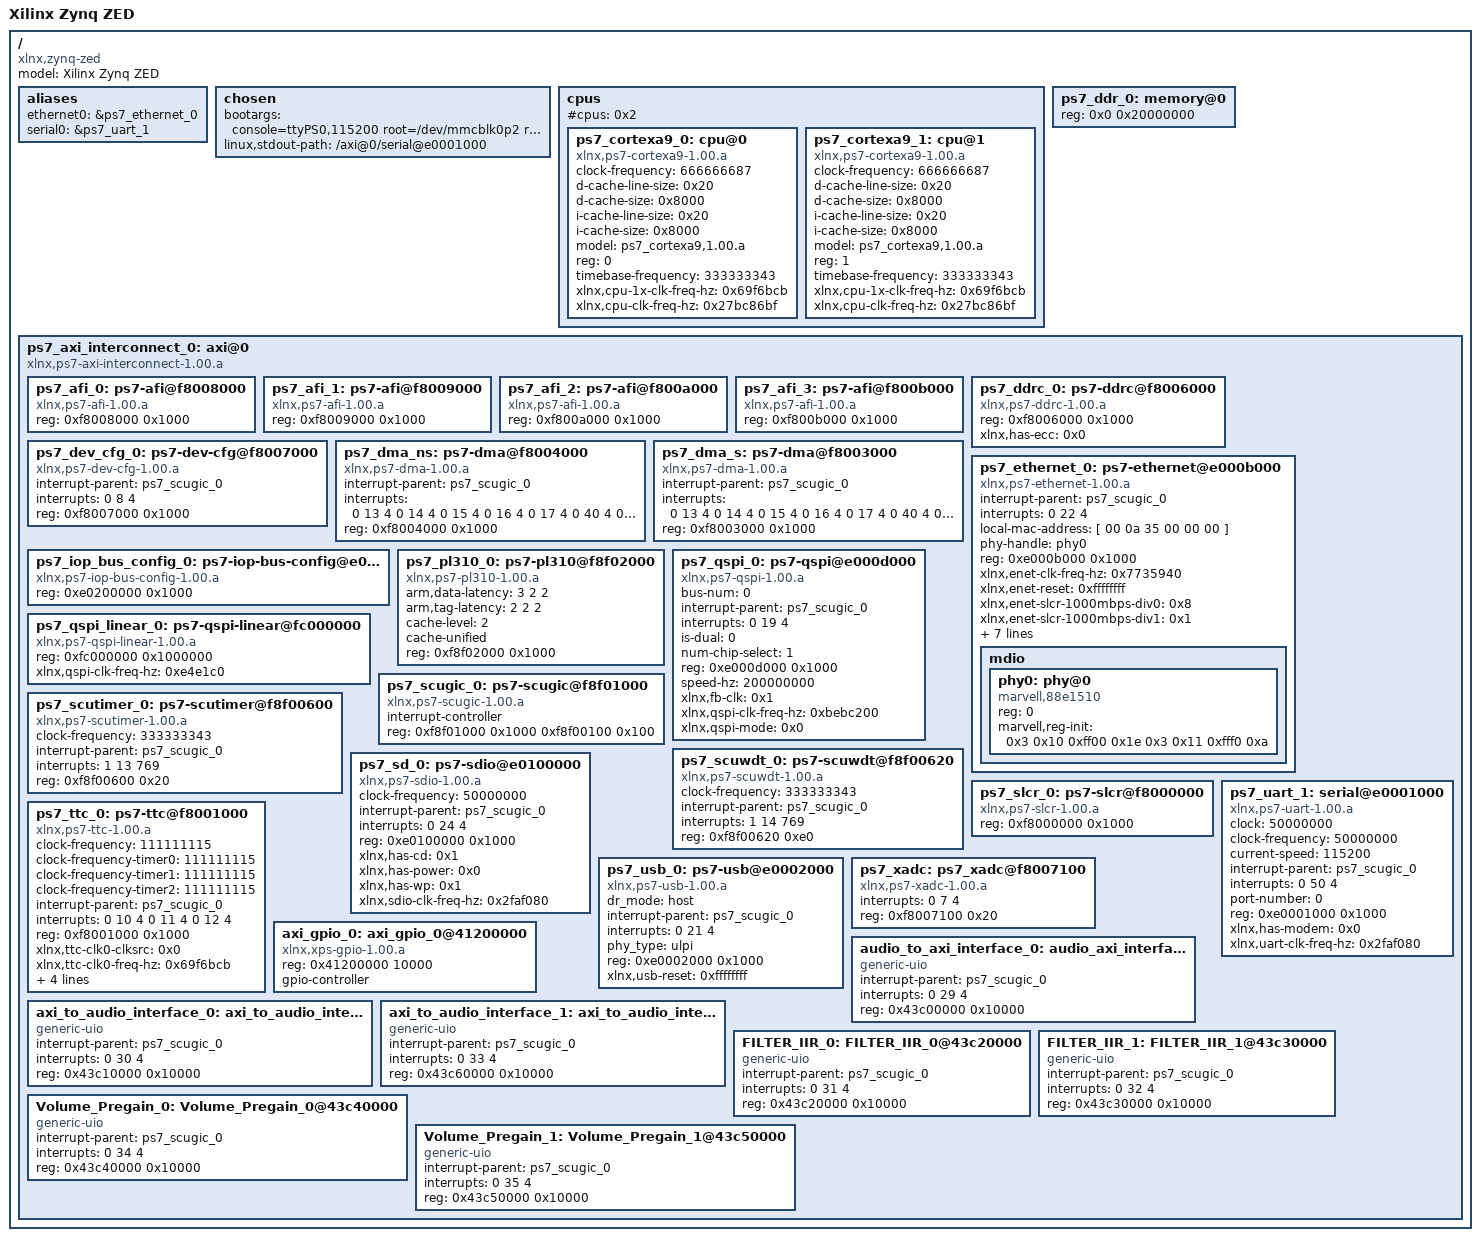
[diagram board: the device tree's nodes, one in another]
/dts-v1/;

/* Root node */
/ {
/* General device description */
    #address-cells = <1>;
    #size-cells = <1>;
    compatible = "xlnx,zynq-zed";
    model = "Xilinx Zynq ZED";

/* Aliases for some devices */
    aliases {
        ethernet0 = &ps7_ethernet_0;
        serial0 = &ps7_uart_1;
    };

/* Some special fields for configuring the linux kernel */
    chosen {
        bootargs = "console=ttyPS0,115200 root=/dev/mmcblk0p2 rw earlyprintk rootfstype=ext4 rootwait devtmpfs.mount=1";
        /* bootargs = "console=ttyPS0,115200 root=/dev/ram rw initrd=0x800000,8M init=/init earlyprintk rootwait devtmpfs.mount=1"; */
        linux,stdout-path = "/axi@0/serial@e0001000";
    };

/* Discribe CPUs */
    cpus {
        #address-cells = <1>;
        #cpus = <0x2>;
        #size-cells = <0>;
        ps7_cortexa9_0: cpu@0 {
            clock-frequency = <666666687>;
            compatible = "xlnx,ps7-cortexa9-1.00.a";
            d-cache-line-size = <0x20>;
            d-cache-size = <0x8000>;
            device_type = "cpu";
            i-cache-line-size = <0x20>;
            i-cache-size = <0x8000>;
            model = "ps7_cortexa9,1.00.a";
            reg = <0>;
            timebase-frequency = <333333343>;
            xlnx,cpu-1x-clk-freq-hz = <0x69f6bcb>;
            xlnx,cpu-clk-freq-hz = <0x27bc86bf>;
        };
        ps7_cortexa9_1: cpu@1 {
            clock-frequency = <666666687>;
            compatible = "xlnx,ps7-cortexa9-1.00.a";
            d-cache-line-size = <0x20>;
            d-cache-size = <0x8000>;
            device_type = "cpu";
            i-cache-line-size = <0x20>;
            i-cache-size = <0x8000>;
            model = "ps7_cortexa9,1.00.a";
            reg = <1>;
            timebase-frequency = <333333343>;
            xlnx,cpu-1x-clk-freq-hz = <0x69f6bcb>;
            xlnx,cpu-clk-freq-hz = <0x27bc86bf>;
        };
    };

/* Memory */
    ps7_ddr_0: memory@0 {
        device_type = "memory";
        reg = < 0x0 0x20000000 >;
    };

/* Describe devices on the AXI bus */
    ps7_axi_interconnect_0: axi@0 {
        #address-cells = <1>;
        #size-cells = <1>;
        compatible = "xlnx,ps7-axi-interconnect-1.00.a", "simple-bus";
        ranges;

        /* PS system internal devices */
        ps7_afi_0: ps7-afi@f8008000 {
            compatible = "xlnx,ps7-afi-1.00.a";
            reg = < 0xf8008000 0x1000 >;
        };
        ps7_afi_1: ps7-afi@f8009000 {
            compatible = "xlnx,ps7-afi-1.00.a";
            reg = < 0xf8009000 0x1000 >;
        };
        ps7_afi_2: ps7-afi@f800a000 {
            compatible = "xlnx,ps7-afi-1.00.a";
            reg = < 0xf800a000 0x1000 >;
        };
        ps7_afi_3: ps7-afi@f800b000 {
            compatible = "xlnx,ps7-afi-1.00.a";
            reg = < 0xf800b000 0x1000 >;
        };

        ps7_ddrc_0: ps7-ddrc@f8006000 {
            compatible = "xlnx,ps7-ddrc-1.00.a";
            reg = < 0xf8006000 0x1000 >;
            xlnx,has-ecc = <0x0>;
        };

        ps7_dev_cfg_0: ps7-dev-cfg@f8007000 {
            compatible = "xlnx,ps7-dev-cfg-1.00.a";
            interrupt-parent = <&ps7_scugic_0>;
            interrupts = < 0 8 4 >;
            reg = < 0xf8007000 0x1000 >;
        };

        ps7_dma_ns: ps7-dma@f8004000 {
            compatible = "xlnx,ps7-dma-1.00.a", "arm,pl330";
            interrupt-parent = <&ps7_scugic_0>;
            interrupts = < 0 13 4 0 14 4 0 15 4 0 16 4 0 17 4 0 40 4 0 41 4 0 42 4 0 43 4 >;
            reg = < 0xf8004000 0x1000 >;
        };

        ps7_dma_s: ps7-dma@f8003000 {
            compatible = "xlnx,ps7-dma-1.00.a", "arm,pl330";
            interrupt-parent = <&ps7_scugic_0>;
            interrupts = < 0 13 4 0 14 4 0 15 4 0 16 4 0 17 4 0 40 4 0 41 4 0 42 4 0 43 4 >;
            reg = < 0xf8003000 0x1000 >;
        };

        ps7_ethernet_0: ps7-ethernet@e000b000 {
            #address-cells = <1>;
            #size-cells = <0>;
            compatible = "xlnx,ps7-ethernet-1.00.a";
            interrupt-parent = <&ps7_scugic_0>;
            interrupts = < 0 22 4 >;
            local-mac-address = [ 00 0a 35 00 00 00 ];
            phy-handle = <&phy0>;
            reg = < 0xe000b000 0x1000 >;
            xlnx,enet-clk-freq-hz = <0x7735940>;
            xlnx,enet-reset = <0xffffffff>;
            xlnx,enet-slcr-1000mbps-div0 = <0x8>;
            xlnx,enet-slcr-1000mbps-div1 = <0x1>;
            xlnx,enet-slcr-100mbps-div0 = <0x8>;
            xlnx,enet-slcr-100mbps-div1 = <0x5>;
            xlnx,enet-slcr-10mbps-div0 = <0x8>;
            xlnx,enet-slcr-10mbps-div1 = <0x32>;
            xlnx,eth-mode = <0x1>;
            xlnx,has-mdio = <0x1>;
            xlnx,ptp-enet-clock = <111111115>;

            mdio {
                #address-cells = <1>;
                #size-cells = <0>;
                phy0: phy@0 {
                    compatible = "marvell,88e1510";
                    device_type = "ethernet-phy";
                    reg = <0>;
                    marvell,reg-init = <0x3 0x10 0xff00 0x1e 0x3 0x11 0xfff0 0xa>;
                };
            };
        };

        ps7_iop_bus_config_0: ps7-iop-bus-config@e0200000 {
            compatible = "xlnx,ps7-iop-bus-config-1.00.a";
            reg = < 0xe0200000 0x1000 >;
        };

        ps7_pl310_0: ps7-pl310@f8f02000 {
            arm,data-latency = < 3 2 2 >;
            arm,tag-latency = < 2 2 2 >;
            cache-level = < 2 >;
            cache-unified;
            compatible = "xlnx,ps7-pl310-1.00.a", "arm,pl310-cache";
            reg = < 0xf8f02000 0x1000 >;
        };

        ps7_qspi_0: ps7-qspi@e000d000 {
            bus-num = <0>;
            compatible = "xlnx,ps7-qspi-1.00.a";
            interrupt-parent = <&ps7_scugic_0>;
            interrupts = < 0 19 4 >;
            is-dual = <0>;
            num-chip-select = <1>;
            reg = < 0xe000d000 0x1000 >;
            speed-hz = <200000000>;
            xlnx,fb-clk = <0x1>;
            xlnx,qspi-clk-freq-hz = <0xbebc200>;
            xlnx,qspi-mode = <0x0>;
        };

        ps7_qspi_linear_0: ps7-qspi-linear@fc000000 {
            compatible = "xlnx,ps7-qspi-linear-1.00.a";
            reg = < 0xfc000000 0x1000000 >;
            xlnx,qspi-clk-freq-hz = <0xe4e1c0>;
        };

        ps7_scugic_0: ps7-scugic@f8f01000 {
            #address-cells = < 2 >;
            #interrupt-cells = < 3 >;
            #size-cells = < 1 >;
            compatible = "xlnx,ps7-scugic-1.00.a", "arm,cortex-a9-gic", "arm,gic";
            interrupt-controller;
            linux,phandle = < 0x1 >;
            phandle = < 0x1 >;
            reg = < 0xf8f01000 0x1000 0xf8f00100 0x100 >;
        };

        ps7_scutimer_0: ps7-scutimer@f8f00600 {
            clock-frequency = <333333343>;
            compatible = "xlnx,ps7-scutimer-1.00.a", "arm,cortex-a9-twd-timer";
            interrupt-parent = <&ps7_scugic_0>;
            interrupts = < 1 13 769 >;
            reg = < 0xf8f00600 0x20 >;
        };

        ps7_scuwdt_0: ps7-scuwdt@f8f00620 {
            clock-frequency = <333333343>;
            /* clock-frequency = <111111111>; */
            compatible = "xlnx,ps7-scuwdt-1.00.a";
            device_type = "watchdog";
            interrupt-parent = <&ps7_scugic_0>;
            interrupts = < 1 14 769 >;
            reg = < 0xf8f00620 0xe0 >;
        };

        ps7_sd_0: ps7-sdio@e0100000 {
            clock-frequency = <50000000>;
            compatible = "xlnx,ps7-sdio-1.00.a", "generic-sdhci";
            interrupt-parent = <&ps7_scugic_0>;
            interrupts = < 0 24 4 >;
            reg = < 0xe0100000 0x1000 >;
            xlnx,has-cd = <0x1>;
            xlnx,has-power = <0x0>;
            xlnx,has-wp = <0x1>;
            xlnx,sdio-clk-freq-hz = <0x2faf080>;
            /* clock-frequency = <0x1fc9f08>; */
        };

        ps7_slcr_0: ps7-slcr@f8000000 {
            compatible = "xlnx,ps7-slcr-1.00.a";
            reg = < 0xf8000000 0x1000 >;
        };

        ps7_ttc_0: ps7-ttc@f8001000 {
            clock-frequency = <111111115>;
            clock-frequency-timer0 = <111111115>;
            clock-frequency-timer1 = <111111115>;
            clock-frequency-timer2 = <111111115>;
            compatible = "xlnx,ps7-ttc-1.00.a";
            interrupt-parent = <&ps7_scugic_0>;
            interrupts = < 0 10 4 0 11 4 0 12 4 >;
            reg = < 0xf8001000 0x1000 >;
            xlnx,ttc-clk0-clksrc = <0x0>;
            xlnx,ttc-clk0-freq-hz = <0x69f6bcb>;
            xlnx,ttc-clk1-clksrc = <0x0>;
            xlnx,ttc-clk1-freq-hz = <0x69f6bcb>;
            xlnx,ttc-clk2-clksrc = <0x0>;
            xlnx,ttc-clk2-freq-hz = <0x69f6bcb>;
        };

        ps7_uart_1: serial@e0001000 {
            clock = <50000000>;
            clock-frequency = <50000000>;
            compatible = "xlnx,ps7-uart-1.00.a", "xlnx,xuartps";
            current-speed = <115200>;
            device_type = "serial";
            interrupt-parent = <&ps7_scugic_0>;
            interrupts = < 0 50 4 >;
            port-number = <0>;
            reg = < 0xe0001000 0x1000 >;
            xlnx,has-modem = <0x0>;
            xlnx,uart-clk-freq-hz = <0x2faf080>;
        };

        ps7_usb_0: ps7-usb@e0002000 {
            compatible = "xlnx,ps7-usb-1.00.a";
            dr_mode = "host";
            interrupt-parent = <&ps7_scugic_0>;
            interrupts = < 0 21 4 >;
            phy_type = "ulpi";
            reg = < 0xe0002000 0x1000 >;
            xlnx,usb-reset = <0xffffffff>;
        };

        ps7_xadc: ps7_xadc@f8007100 {
            compatible = "xlnx,ps7-xadc-1.00.a";
            interrupts = < 0 7 4 >;
            reg = < 0xf8007100 0x20 >;
        };

        axi_gpio_0: axi_gpio_0@41200000 {
            compatible = "xlnx,xps-gpio-1.00.a";
            reg = < 0x41200000 10000 >;
            gpio-controller;
        };

	audio_to_axi_interface_0: audio_axi_interface_0@43c00000 {
            compatible = "generic-uio";
            interrupt-parent = <&ps7_scugic_0>;
            interrupts = < 0 29 4 >;
            reg = < 0x43c00000 0x10000 >;
        };

	axi_to_audio_interface_0: axi_to_audio_interface_0@43c10000 {
            compatible = "generic-uio";
            interrupt-parent = <&ps7_scugic_0>;
            interrupts = < 0 30 4 >;
            reg = < 0x43c10000 0x10000 >;
        };

	axi_to_audio_interface_1: axi_to_audio_interface_1@43c60000 {
            compatible = "generic-uio";
            interrupt-parent = <&ps7_scugic_0>;
            interrupts = < 0 33 4 >;
            reg = < 0x43c60000 0x10000 >;
        };

	FILTER_IIR_0: FILTER_IIR_0@43c20000 {
            compatible = "generic-uio";
            interrupt-parent = <&ps7_scugic_0>;
            interrupts = < 0 31 4 >;
            reg = < 0x43c20000 0x10000 >;
        };

	FILTER_IIR_1: FILTER_IIR_1@43c30000 {
            compatible = "generic-uio";
            interrupt-parent = <&ps7_scugic_0>;
            interrupts = < 0 32 4 >;
            reg = < 0x43c30000 0x10000 >;
        };

	Volume_Pregain_0: Volume_Pregain_0@43c40000 {
            compatible = "generic-uio";
            interrupt-parent = <&ps7_scugic_0>;
            interrupts = < 0 34 4 >;
            reg = < 0x43c40000 0x10000 >;
        };

	Volume_Pregain_1: Volume_Pregain_1@43c50000 {
            compatible = "generic-uio";
            interrupt-parent = <&ps7_scugic_0>;
            interrupts = < 0 35 4 >;
            reg = < 0x43c50000 0x10000 >;
        };

    };
};
